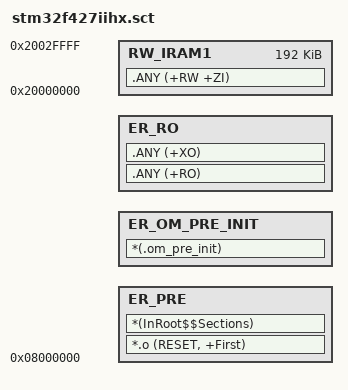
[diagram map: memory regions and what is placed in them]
; *************************************************************
; *** Scatter-Loading Description File generated by uVision ***
; *************************************************************
; 修改：
;   ER_PRE      —— RESET / InRoot$$Sections（向量表 + C 运行时）
;   ER_OM_PRE_INIT —— .om_pre_init（OM_PRE_INIT 回调，独立执行域，
;                      armlink 自动生成 Image$$ER_OM_PRE_INIT$$Base/Limit）
;   ER_RO       —— 其余 RO/RW/ZI 数据

LR_IROM1 0x08000000 0x00200000  {    ; load region size_region
  ER_PRE 0x08000000  {               ; 向量表 + C 运行时库
   *.o (RESET, +First)
   *(InRoot$$Sections)
  }
  ER_OM_PRE_INIT +0  {               ; OM_PRE_INIT 回调列表
   *(.om_pre_init)
  }
  ER_RO +0  {                         ; 其余只读数据 + 代码
   .ANY (+RO)
   .ANY (+XO)
  }
  RW_IRAM1 0x20000000 0x00030000  {  ; RW data
   .ANY (+RW +ZI)
  }
}
